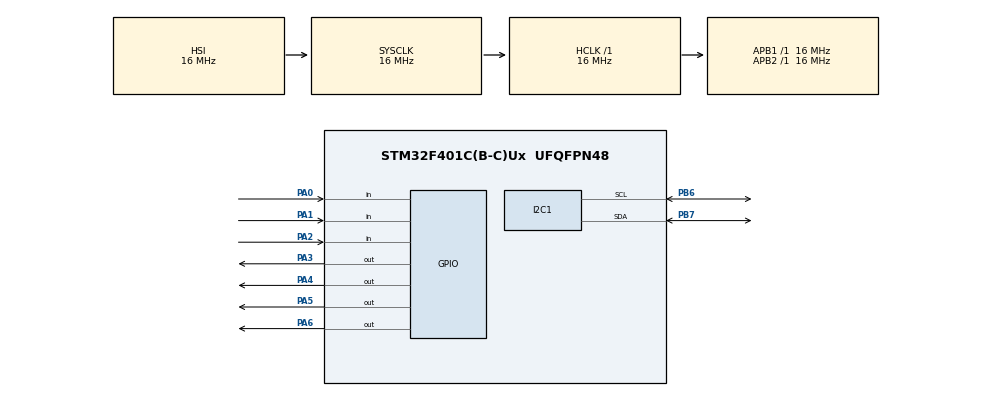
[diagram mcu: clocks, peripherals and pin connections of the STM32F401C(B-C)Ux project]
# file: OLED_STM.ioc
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I2C1.I2C_Mode=I2C_Fast
Mcu.Family=STM32F4
Mcu.Name=STM32F401C(B-C)Ux
Mcu.Package=UFQFPN48
NVIC.PriorityGroup=NVIC_PRIORITYGROUP_4
PA0-WKUP.Signal=GPIO_Input
PA1.Signal=GPIO_Input
PA13.Mode=Serial_Wire
PA13.Signal=SYS_JTMS-SWDIO
PA14.Mode=Serial_Wire
PA14.Signal=SYS_JTCK-SWCLK
PA2.Signal=GPIO_Input
PA3.Signal=GPIO_Output
PA4.Signal=GPIO_Output
PA5.Signal=GPIO_Output
PA6.Signal=GPIO_Output
PB6.Mode=I2C
PB6.Signal=I2C1_SCL
PB7.Mode=I2C
PB7.Signal=I2C1_SDA
ProjectManager.HeapSize=0x200
ProjectManager.StackSize=0x400
ProjectManager.TargetToolchain=STM32CubeIDE
RCC.AHBFreq_Value=16000000
RCC.APB1Freq_Value=16000000
RCC.APB2Freq_Value=16000000
RCC.CortexFreq_Value=16000000
RCC.HSE_VALUE=25000000
RCC.HSI_VALUE=16000000
RCC.LSE_VALUE=32768
RCC.SYSCLKFreq_VALUE=16000000
RCC.VCOOutputFreq_Value=192000000
board=custom

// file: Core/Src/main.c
/* USER CODE BEGIN Header */
/**
  ******************************************************************************
  * @file           : main.c
  * @brief          : Main program body
  ******************************************************************************
  * @attention
  *
  * Copyright (c) 2024 STMicroelectronics.
  * All rights reserved.
  *
  * This software is licensed under terms that can be found in the LICENSE file
  * in the root directory of this software component.
  * If no LICENSE file comes with this software, it is provided AS-IS.
  *
  ******************************************************************************
  */
/* USER CODE END Header */
#include "main.h"

/* USER CODE BEGIN Includes */
#include "fonts.h"
#include "ssd1306.h"
/* USER CODE END Includes */

/* USER CODE BEGIN PD */
#define R1_PORT GPIOA
#define R1_PIN GPIO_PIN_3

#define R2_PORT GPIOA
#define R2_PIN GPIO_PIN_4

#define R3_PORT GPIOA
#define R3_PIN GPIO_PIN_5

#define R4_PORT GPIOA
#define R4_PIN GPIO_PIN_6

#define C1_PORT GPIOA
#define C1_PIN GPIO_PIN_0

#define C2_PORT GPIOA
#define C2_PIN GPIO_PIN_1

#define C3_PORT GPIOA
#define C3_PIN GPIO_PIN_2

/* USER CODE END PD */

I2C_HandleTypeDef hi2c1;
GPIO_InitTypeDef GPIO_InitStructPrivate = {0};
uint32_t previousMillis = 0;
uint32_t currentMillis = 0;
uint8_t keyPressed = 0;

void SystemClock_Config(void);
static void MX_GPIO_Init(void);
static void MX_I2C1_Init(void);

/* USER CODE BEGIN 0 */
uint8_t key;

char read_keypad (void)
{
	/* Make ROW 1 LOW and all other ROWs HIGH */
	HAL_GPIO_WritePin (R1_PORT, R1_PIN, GPIO_PIN_RESET);  //Pull the R1 low
	HAL_GPIO_WritePin (R2_PORT, R2_PIN, GPIO_PIN_SET);  // Pull the R2 High
	HAL_GPIO_WritePin (R3_PORT, R3_PIN, GPIO_PIN_SET);  // Pull the R3 High
	HAL_GPIO_WritePin (R4_PORT, R4_PIN, GPIO_PIN_SET);  // Pull the R4 High

	if (!(HAL_GPIO_ReadPin (C1_PORT, C1_PIN)))   // if the Col 1 is low
	{
		while (!(HAL_GPIO_ReadPin (C1_PORT, C1_PIN)));   // wait till the button is pressed
		return '1';
	}

	if (!(HAL_GPIO_ReadPin (C2_PORT, C2_PIN)))   // if the Col 2 is low
	{
		while (!(HAL_GPIO_ReadPin (C2_PORT, C2_PIN)));   // wait till the button is pressed
		return '2';
	}

	if (!(HAL_GPIO_ReadPin (C3_PORT, C3_PIN)))   // if the Col 3 is low
	{
		while (!(HAL_GPIO_ReadPin (C3_PORT, C3_PIN)));   // wait till the button is pressed
		return '3';
	}

	/* Make ROW 2 LOW and all other ROWs HIGH */
	HAL_GPIO_WritePin (R1_PORT, R1_PIN, GPIO_PIN_SET);  //Pull the R1 low
	HAL_GPIO_WritePin (R2_PORT, R2_PIN, GPIO_PIN_RESET);  // Pull the R2 High
	HAL_GPIO_WritePin (R3_PORT, R3_PIN, GPIO_PIN_SET);  // Pull the R3 High
	HAL_GPIO_WritePin (R4_PORT, R4_PIN, GPIO_PIN_SET);  // Pull the R4 High

	if (!(HAL_GPIO_ReadPin (C1_PORT, C1_PIN)))   // if the Col 1 is low
	{
		while (!(HAL_GPIO_ReadPin (C1_PORT, C1_PIN)));   // wait till the button is pressed
		return '4';
	}

	if (!(HAL_GPIO_ReadPin (C2_PORT, C2_PIN)))   // if the Col 2 is low
	{
		while (!(HAL_GPIO_ReadPin (C2_PORT, C2_PIN)));   // wait till the button is pressed
		return '5';
	}

	if (!(HAL_GPIO_ReadPin (C3_PORT, C3_PIN)))   // if the Col 3 is low
	{
		while (!(HAL_GPIO_ReadPin (C3_PORT, C3_PIN)));   // wait till the button is pressed
		return '6';
	}

	/* Make ROW 3 LOW and all other ROWs HIGH */
	HAL_GPIO_WritePin (R1_PORT, R1_PIN, GPIO_PIN_SET);  //Pull the R1 low
	HAL_GPIO_WritePin (R2_PORT, R2_PIN, GPIO_PIN_SET);  // Pull the R2 High
	HAL_GPIO_WritePin (R3_PORT, R3_PIN, GPIO_PIN_RESET);  // Pull the R3 High
	HAL_GPIO_WritePin (R4_PORT, R4_PIN, GPIO_PIN_SET);  // Pull the R4 High

	if (!(HAL_GPIO_ReadPin (C1_PORT, C1_PIN)))   // if the Col 1 is low
	{
		while (!(HAL_GPIO_ReadPin (C1_PORT, C1_PIN)));   // wait till the button is pressed
		return '7';
	}

	if (!(HAL_GPIO_ReadPin (C2_PORT, C2_PIN)))   // if the Col 2 is low
	{
		while (!(HAL_GPIO_ReadPin (C2_PORT, C2_PIN)));   // wait till the button is pressed
		return '8';
	}

	if (!(HAL_GPIO_ReadPin (C3_PORT, C3_PIN)))   // if the Col 3 is low
	{
		while (!(HAL_GPIO_ReadPin (C3_PORT, C3_PIN)));   // wait till the button is pressed
		return '9';
	}

	/* Make ROW 4 LOW and all other ROWs HIGH */
	HAL_GPIO_WritePin (R1_PORT, R1_PIN, GPIO_PIN_SET);  //Pull the R1 low
	HAL_GPIO_WritePin (R2_PORT, R2_PIN, GPIO_PIN_SET);  // Pull the R2 High
	HAL_GPIO_WritePin (R3_PORT, R3_PIN, GPIO_PIN_SET);  // Pull the R3 High
	HAL_GPIO_WritePin (R4_PORT, R4_PIN, GPIO_PIN_RESET);  // Pull the R4 High

	if (!(HAL_GPIO_ReadPin (C1_PORT, C1_PIN)))   // if the Col 1 is low
	{
		while (!(HAL_GPIO_ReadPin (C1_PORT, C1_PIN)));   // wait till the button is pressed
		return '*';
	}

	if (!(HAL_GPIO_ReadPin (C2_PORT, C2_PIN)))   // if the Col 2 is low
	{
		while (!(HAL_GPIO_ReadPin (C2_PORT, C2_PIN)));   // wait till the button is pressed
		return '0';
	}

	if (!(HAL_GPIO_ReadPin (C3_PORT, C3_PIN)))   // if the Col 3 is low
	{
		while (!(HAL_GPIO_ReadPin (C3_PORT, C3_PIN)));   // wait till the button is pressed
		return '#';
	}

}

/* USER CODE END 0 */

int main(void)
{

  /* MCU Configuration--------------------------------------------------------*/

  /* Reset of all peripherals, Initializes the Flash interface and the Systick. */
  HAL_Init();

  /* Configure the system clock */
  SystemClock_Config();

  /* Initialize all configured peripherals */
  MX_GPIO_Init();
  MX_I2C1_Init();
  /* USER CODE BEGIN 2 */
  SSD1306_Init();
//    char snum[5];

    SSD1306_GotoXY (0,0);
    SSD1306_Puts ("Enter PIN", &Font_11x18, 1);
    SSD1306_UpdateScreen();
    HAL_Delay (1000);

    /*HAL_GPIO_WritePin(GPIOA, GPIO_PIN_0, 1);
    HAL_GPIO_WritePin(GPIOA, GPIO_PIN_1, 1);
    HAL_GPIO_WritePin(GPIOA, GPIO_PIN_2, 1);
*/

  /* USER CODE END 2 */

  /* Infinite loop */
  /* USER CODE BEGIN WHILE */
  while (1)
  {
	    char digit = read_keypad ();
		SSD1306_GotoXY(0, 30);
		//SSD1306_Clear();
		SSD1306_Putc(digit, &Font_11x18, 1);
		SSD1306_UpdateScreen();
		HAL_Delay(1000);

  }

    /* USER CODE END WHILE */

}
void SystemClock_Config(void)
{
  RCC_OscInitTypeDef RCC_OscInitStruct = {0};
  RCC_ClkInitTypeDef RCC_ClkInitStruct = {0};

  /** Configure the main internal regulator output voltage
  */
  __HAL_RCC_PWR_CLK_ENABLE();
  __HAL_PWR_VOLTAGESCALING_CONFIG(PWR_REGULATOR_VOLTAGE_SCALE2);

  /** Initializes the RCC Oscillators according to the specified parameters
  * in the RCC_OscInitTypeDef structure.
  */
  RCC_OscInitStruct.OscillatorType = RCC_OSCILLATORTYPE_HSI;
  RCC_OscInitStruct.HSIState = RCC_HSI_ON;
  RCC_OscInitStruct.HSICalibrationValue = RCC_HSICALIBRATION_DEFAULT;
  RCC_OscInitStruct.PLL.PLLState = RCC_PLL_NONE;
  if (HAL_RCC_OscConfig(&RCC_OscInitStruct) != HAL_OK)
  {
    Error_Handler();
  }

  /** Initializes the CPU, AHB and APB buses clocks
  */
  RCC_ClkInitStruct.ClockType = RCC_CLOCKTYPE_HCLK|RCC_CLOCKTYPE_SYSCLK
                              |RCC_CLOCKTYPE_PCLK1|RCC_CLOCKTYPE_PCLK2;
  RCC_ClkInitStruct.SYSCLKSource = RCC_SYSCLKSOURCE_HSI;
  RCC_ClkInitStruct.AHBCLKDivider = RCC_SYSCLK_DIV1;
  RCC_ClkInitStruct.APB1CLKDivider = RCC_HCLK_DIV1;
  RCC_ClkInitStruct.APB2CLKDivider = RCC_HCLK_DIV1;

  if (HAL_RCC_ClockConfig(&RCC_ClkInitStruct, FLASH_LATENCY_0) != HAL_OK)
  {
    Error_Handler();
  }
}

static void MX_I2C1_Init(void)
{

  hi2c1.Instance = I2C1;
  hi2c1.Init.ClockSpeed = 400000;
  hi2c1.Init.DutyCycle = I2C_DUTYCYCLE_2;
  hi2c1.Init.OwnAddress1 = 0;
  hi2c1.Init.AddressingMode = I2C_ADDRESSINGMODE_7BIT;
  hi2c1.Init.DualAddressMode = I2C_DUALADDRESS_DISABLE;
  hi2c1.Init.OwnAddress2 = 0;
  hi2c1.Init.GeneralCallMode = I2C_GENERALCALL_DISABLE;
  hi2c1.Init.NoStretchMode = I2C_NOSTRETCH_DISABLE;
  if (HAL_I2C_Init(&hi2c1) != HAL_OK)
  {
    Error_Handler();
  }

}

static void MX_GPIO_Init(void)
{
	GPIO_InitTypeDef GPIO_InitStruct = {0};

	  /* GPIO Ports Clock Enable */
	  __HAL_RCC_GPIOD_CLK_ENABLE();
	  __HAL_RCC_GPIOA_CLK_ENABLE();
	  __HAL_RCC_GPIOB_CLK_ENABLE();

	  /*Configure GPIO pin Output Level */
	  HAL_GPIO_WritePin(GPIOA, GPIO_PIN_4|GPIO_PIN_5|GPIO_PIN_6|GPIO_PIN_7, GPIO_PIN_RESET);

	  /*Configure GPIO pins : PA0 PA1 PA2 PA3 */
	  GPIO_InitStruct.Pin = GPIO_PIN_0|GPIO_PIN_1|GPIO_PIN_2|GPIO_PIN_3;
	  GPIO_InitStruct.Mode = GPIO_MODE_INPUT;
	  GPIO_InitStruct.Pull = GPIO_PULLUP;
	  HAL_GPIO_Init(GPIOA, &GPIO_InitStruct);

	  /*Configure GPIO pins : PA4 PA5 PA6 PA7 */
	  GPIO_InitStruct.Pin = GPIO_PIN_4|GPIO_PIN_5|GPIO_PIN_6|GPIO_PIN_7;
	  GPIO_InitStruct.Mode = GPIO_MODE_OUTPUT_PP;
	  GPIO_InitStruct.Pull = GPIO_NOPULL;
	  GPIO_InitStruct.Speed = GPIO_SPEED_FREQ_LOW;
	  HAL_GPIO_Init(GPIOA, &GPIO_InitStruct);

}

/* USER CODE BEGIN 4 */
void HAL_GPIO_EXTI_Callback(uint16_t GPIO_Pin)
{
  /*currentMillis = HAL_GetTick();
  if (currentMillis - previousMillis > 10) {
    Configure GPIO pins : PB6 PB7 PB8 PB9 to GPIO_INPUT
    GPIO_InitStructPrivate.Pin = GPIO_PIN_3|GPIO_PIN_4|GPIO_PIN_5|GPIO_PIN_6;
    GPIO_InitStructPrivate.Mode = GPIO_MODE_INPUT;
    GPIO_InitStructPrivate.Pull = GPIO_NOPULL;
    GPIO_InitStructPrivate.Speed = GPIO_SPEED_FREQ_LOW;
    HAL_GPIO_Init(GPIOA, &GPIO_InitStructPrivate);

    HAL_GPIO_WritePin(GPIOA, GPIO_PIN_0, 0);
    HAL_GPIO_WritePin(GPIOA, GPIO_PIN_1, 0);
    HAL_GPIO_WritePin(GPIOA, GPIO_PIN_2, 1);
    if(GPIO_Pin == GPIO_PIN_6 && HAL_GPIO_ReadPin(GPIOA, GPIO_PIN_6))
    {
      keyPressed = 35; //ASCII value of #
    }
    else if(GPIO_Pin == GPIO_PIN_5 && HAL_GPIO_ReadPin(GPIOA, GPIO_PIN_5))
    {
      keyPressed = 57; //ASCII value of 9
    }
    else if(GPIO_Pin == GPIO_PIN_4 && HAL_GPIO_ReadPin(GPIOA, GPIO_PIN_4))
    {
      keyPressed = 54; //ASCII value of 6
    }
    else if(GPIO_Pin == GPIO_PIN_3 && HAL_GPIO_ReadPin(GPIOA, GPIO_PIN_3))
    {
      keyPressed = 51; //ASCII value of 3
    }

    HAL_GPIO_WritePin(GPIOA, GPIO_PIN_0, 0);
    HAL_GPIO_WritePin(GPIOA, GPIO_PIN_1, 1);
    HAL_GPIO_WritePin(GPIOA, GPIO_PIN_2, 0);
    if(GPIO_Pin == GPIO_PIN_6 && HAL_GPIO_ReadPin(GPIOA, GPIO_PIN_6))
    {
      keyPressed = 48; //ASCII value of 0
    }
    else if(GPIO_Pin == GPIO_PIN_5 && HAL_GPIO_ReadPin(GPIOA, GPIO_PIN_5))
    {
      keyPressed = 56; //ASCII value of 8
    }
    else if(GPIO_Pin == GPIO_PIN_4 && HAL_GPIO_ReadPin(GPIOA, GPIO_PIN_4))
    {
      keyPressed = 53; //ASCII value of 5
    }
    else if(GPIO_Pin == GPIO_PIN_3 && HAL_GPIO_ReadPin(GPIOA, GPIO_PIN_3))
    {
      keyPressed = 50; //ASCII value of 2
    }

    HAL_GPIO_WritePin(GPIOA, GPIO_PIN_0, 1);
    HAL_GPIO_WritePin(GPIOA, GPIO_PIN_1, 0);
    HAL_GPIO_WritePin(GPIOA, GPIO_PIN_2, 0);
    if(GPIO_Pin == GPIO_PIN_6 && HAL_GPIO_ReadPin(GPIOA, GPIO_PIN_6))
    {
      keyPressed = 42; //ASCII value of *
    }
    else if(GPIO_Pin == GPIO_PIN_5 && HAL_GPIO_ReadPin(GPIOA, GPIO_PIN_5))
    {
      keyPressed = 55; //ASCII value of 7
    }
    else if(GPIO_Pin == GPIO_PIN_4 && HAL_GPIO_ReadPin(GPIOA, GPIO_PIN_4))
    {
      keyPressed = 52; //ASCII value of 4
    }
    else if(GPIO_Pin == GPIO_PIN_3 && HAL_GPIO_ReadPin(GPIOA, GPIO_PIN_3))
    {
      keyPressed = 49; //ASCII value of 1
    }

    HAL_GPIO_WritePin(GPIOA, GPIO_PIN_0, 1);
    HAL_GPIO_WritePin(GPIOA, GPIO_PIN_1, 1);
    HAL_GPIO_WritePin(GPIOA, GPIO_PIN_2, 1);
    Configure GPIO pins : PB6 PB7 PB8 PB9 back to EXTI
    GPIO_InitStructPrivate.Mode = GPIO_MODE_IT_RISING;
    GPIO_InitStructPrivate.Pull = GPIO_PULLDOWN;
    HAL_GPIO_Init(GPIOA, &GPIO_InitStructPrivate);
    previousMillis = currentMillis;
  }*/
}
/* USER CODE END 4 */

void Error_Handler(void)
{
  __disable_irq();
  while (1)
  {
  }
}
